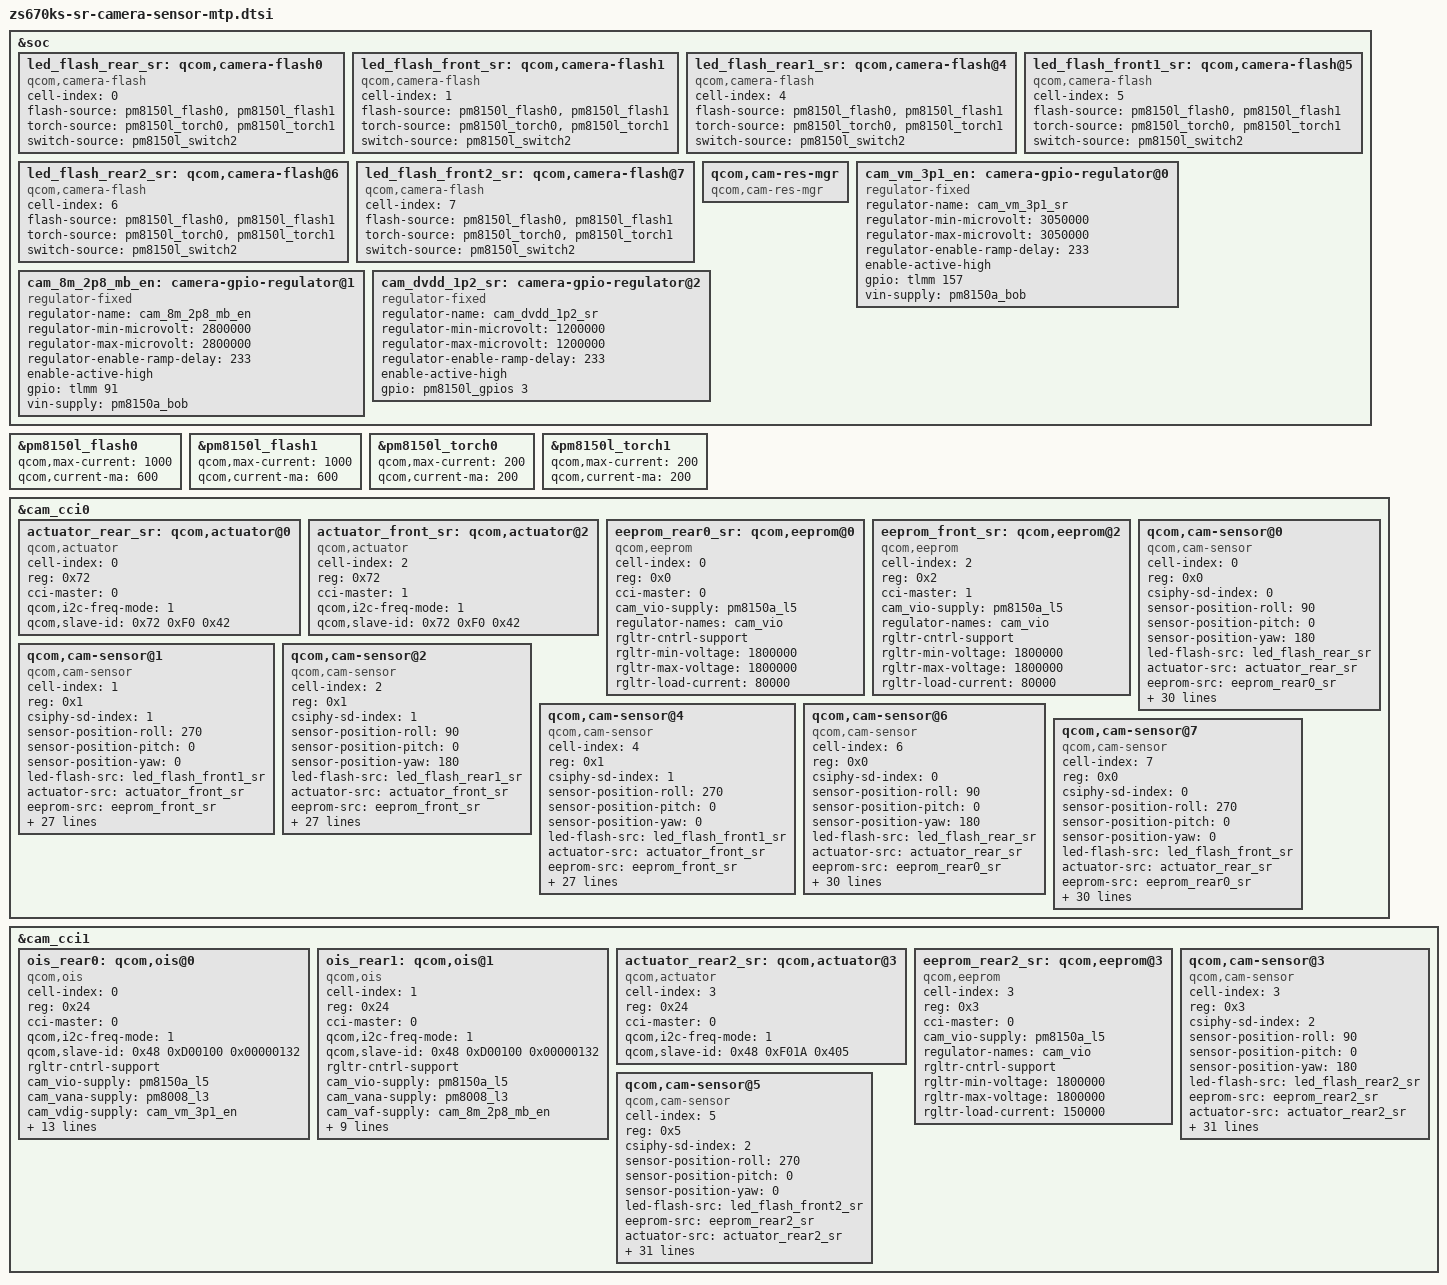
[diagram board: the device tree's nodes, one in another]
#include <dt-bindings/clock/qcom,camcc-kona.h>

&soc {
	led_flash_rear_sr: qcom,camera-flash0 {
		cell-index = <0>;
		compatible = "qcom,camera-flash";
		flash-source = <&pm8150l_flash0 &pm8150l_flash1>;
		torch-source = <&pm8150l_torch0 &pm8150l_torch1>;
		switch-source = <&pm8150l_switch2>;
		status = "ok";
	};//686_rear

	led_flash_front_sr: qcom,camera-flash1 {
		cell-index = <1>;
		compatible = "qcom,camera-flash";
		flash-source = <&pm8150l_flash0 &pm8150l_flash1>;
		torch-source = <&pm8150l_torch0 &pm8150l_torch1>;
		switch-source = <&pm8150l_switch2>;
		status = "ok";
	};//686_front

	led_flash_rear1_sr: qcom,camera-flash@4 {
		cell-index = <4>;
		compatible = "qcom,camera-flash";
		flash-source = <&pm8150l_flash0 &pm8150l_flash1>;
		torch-source = <&pm8150l_torch0 &pm8150l_torch1>;
		switch-source = <&pm8150l_switch2>;
		status = "ok";
	};//363_rear

	led_flash_front1_sr: qcom,camera-flash@5 {
		cell-index = <5>;
		compatible = "qcom,camera-flash";
		flash-source = <&pm8150l_flash0 &pm8150l_flash1>;
		torch-source = <&pm8150l_torch0 &pm8150l_torch1>;
		switch-source = <&pm8150l_switch2>;
		status = "ok";
	};//363_front

	led_flash_rear2_sr: qcom,camera-flash@6 {
		cell-index = <6>;
		compatible = "qcom,camera-flash";
		flash-source = <&pm8150l_flash0 &pm8150l_flash1>;
		torch-source = <&pm8150l_torch0 &pm8150l_torch1>;
		switch-source = <&pm8150l_switch2>;
		status = "ok";
	};//ov_rear


	led_flash_front2_sr: qcom,camera-flash@7 {
		cell-index = <7>;
		compatible = "qcom,camera-flash";
		flash-source = <&pm8150l_flash0 &pm8150l_flash1>;
		torch-source = <&pm8150l_torch0 &pm8150l_torch1>;
		switch-source = <&pm8150l_switch2>;
		status = "ok";
	};//ov_front


	qcom,cam-res-mgr {
		compatible = "qcom,cam-res-mgr";
		status = "ok";
	};
	//IMX686 VM 3.1V
	cam_vm_3p1_en: camera-gpio-regulator@0 {
		compatible = "regulator-fixed";
		regulator-name = "cam_vm_3p1_sr";
		regulator-min-microvolt = <3050000>;
		regulator-max-microvolt = <3050000>;
		regulator-enable-ramp-delay = <233>;
		enable-active-high;
		gpio = <&tlmm 157 0>;
		vin-supply = <&pm8150a_bob>;
	};
	cam_8m_2p8_mb_en: camera-gpio-regulator@1 {
		compatible = "regulator-fixed";
		regulator-name = "cam_8m_2p8_mb_en";
		regulator-min-microvolt = <2800000>;
		regulator-max-microvolt = <2800000>;
		regulator-enable-ramp-delay = <233>;
		enable-active-high;
		gpio = <&tlmm 91 0>;
		vin-supply = <&pm8150a_bob>;
	};

	//AVDD  CAM_DVDD_1P2 OV08A10
	cam_dvdd_1p2_sr: camera-gpio-regulator@2 {
		compatible = "regulator-fixed";
		regulator-name = "cam_dvdd_1p2_sr";
		regulator-min-microvolt = <1200000>;
		regulator-max-microvolt = <1200000>;
		regulator-enable-ramp-delay = <233>;
		enable-active-high;
		gpio = <&pm8150l_gpios 3 0>;
		//vin-supply = <&pm8150a-s4>;
	};
};
	&pm8150l_flash0 {
		qcom,max-current = <1000>;
		qcom,current-ma = <600>;
	};

	&pm8150l_flash1 {
		qcom,max-current = <1000>;
		qcom,current-ma = <600>;
	};
	&pm8150l_torch0 {
		qcom,max-current = <200>;
		qcom,current-ma = <200>;
	};

	&pm8150l_torch1 {
		qcom,max-current = <200>;
		qcom,current-ma = <200>;
	};
&cam_cci0 {
	
	actuator_rear_sr: qcom,actuator@0 { //for imx686 LC898249
		cell-index = <0>;
		reg = <0x72>;
		compatible = "qcom,actuator";
		cci-master = <0>;
		qcom,i2c-freq-mode = <1>;
		qcom,slave-id = <0x72 0xF0 0x42>;
		status = "ok";
  };


	//########### IMX363 ###########
	actuator_front_sr: qcom,actuator@2 {
		cell-index = <2>;
		reg = <0x72>;
		compatible = "qcom,actuator";
		cci-master = <1>;
		qcom,i2c-freq-mode = <1>;
		qcom,slave-id = <0x72 0xF0 0x42>;
		status = "ok";
	};

	eeprom_rear0_sr: qcom,eeprom@0 {
		cell-index = <0>;
		reg = <0x0>;
		cci-master = <0>;
		compatible = "qcom,eeprom";
		cam_vio-supply = <&pm8150a_l5>;    //MCAM0_DOVDD_T_1P8
		regulator-names = "cam_vio";
		rgltr-cntrl-support;
		rgltr-min-voltage = <1800000>;
		rgltr-max-voltage = <1800000>;
		rgltr-load-current = <80000>;
		status = "ok";
	}; 

	eeprom_front_sr: qcom,eeprom@2{
		cell-index = <2>;
		reg = <0x2>;
		cci-master = <1>;
		compatible = "qcom,eeprom";
	 	cam_vio-supply = <&pm8150a_l5>;    //PM8008_LDO6_1P8
		regulator-names = "cam_vio";
		rgltr-cntrl-support;
		rgltr-min-voltage = <1800000>;
		rgltr-max-voltage = <1800000>;
		rgltr-load-current = <80000>;
		status = "ok";
	};

	//########### imx686h_rear_16M ###########
	qcom,cam-sensor@0 {
		cell-index = <0>;
		compatible = "qcom,cam-sensor";
		reg = <0x0>;
		csiphy-sd-index = <0>;
		sensor-position-roll = <90>;
		sensor-position-pitch = <0>;
		sensor-position-yaw = <180>;
		led-flash-src = <&led_flash_rear_sr>;
		actuator-src = <&actuator_rear_sr>;
 		eeprom-src = <&eeprom_rear0_sr>;
		ois-src = <&ois_rear0>;
		cam_vio-supply = <&pm8008_l7>;          //CAM_AVDD1_2P9 
		cam_vana-supply = <&pm8008_l6>;      //CAM_AVDD_1P8 
		cam_v_custom1-supply = <&pm8150a_l5>;    //MCAM0_DOVDD_T_1P8 
		cam_v_custom2-supply = <&pm8008_l3>;    //MCAM0_DOVDD_T_2P9	
		cam_vdig-supply = <&pm8008_l1>;         //MCAM0_DVDD_T_1P1 
		cam_vaf-supply = <&cam_vm_3p1_en>;          //CAM0_VM_3P1_MB
		cam_clk-supply = <&titan_top_gdsc>;
		regulator-names = "cam_vio", "cam_vana", "cam_v_custom1","cam_v_custom2", "cam_vdig", "cam_vaf", "cam_clk";
		rgltr-cntrl-support;
		rgltr-min-voltage = <2950000 1850000 1800000 2900000 1104000 3050000 0>;
		rgltr-max-voltage = <2950000 1850000 1800000 2900000 1104000 3050000 0>;
		rgltr-load-current = <0 80000 80000 300000 0 0 0>;
		gpio-no-mux = <0>;
		pinctrl-names = "cam_default", "cam_suspend";
		pinctrl-0 = <&cam_sensor_mclk0_active>;
		pinctrl-1 = <&cam_sensor_mclk0_suspend>;
		gpios = <&tlmm 94 0>,
			<&tlmm 93 0>;
		gpio-reset = <1>;
		gpio-req-tbl-num = <0 1>;
		gpio-req-tbl-flags = <1 0>;
		gpio-req-tbl-label = "CAMIF_MCLK0",
					"CAM_RESET0";
		sensor-mode = <0>;
		cci-master = <0>;
		status = "ok";
		clocks = <&clock_camcc CAM_CC_MCLK0_CLK>;
		clock-names = "cam_clk";
		clock-cntl-level = "turbo";
		clock-rates = <19200000>;
	};


	//########### IMX363 front for 3rd Party ###########
	qcom,cam-sensor@1 {
		cell-index = <1>;
		compatible = "qcom,cam-sensor";
		reg = <0x1>;
		csiphy-sd-index = <1>;
		sensor-position-roll = <270>;
		sensor-position-pitch = <0>;
		sensor-position-yaw = <0>;
		led-flash-src = <&led_flash_front1_sr>;
		actuator-src = <&actuator_front_sr>;
		eeprom-src = <&eeprom_front_sr>;
		cam_vaf-supply = <&pm8150a_l7>;          //MVCM_2P8
		cam_vio-supply = <&pm8150a_l5>;			//CAM_DOVDD_F_1P8
		cam_vana-supply = <&pm8008_l4>;	//l4p cc wrong		//CAM_AVDD_F_2P8
		cam_vdig-supply = <&pm8008_l2>;		//MCAM0_DVDD_T1_1P1
		cam_clk-supply = <&titan_top_gdsc>;
		regulator-names = "cam_vaf", "cam_vio", "cam_vana", "cam_vdig", "cam_clk";
		rgltr-cntrl-support;
		rgltr-min-voltage = <2900000 1800000 2800000 1050000 0>;
		rgltr-max-voltage = <2900000 1800000 2800000 1050000 0>;
		rgltr-load-current = <140000 80000 80000 1050000 0 >;
		gpio-no-mux = <0>;
		pinctrl-names = "cam_default", "cam_suspend";
	 	pinctrl-0 = <&cam_sensor_mclk1_active>;
		pinctrl-1 = <&cam_sensor_mclk1_suspend>;
		gpios = <&tlmm 95 0>,
			<&tlmm 92 0>;
		gpio-reset = <1>;
		gpio-req-tbl-num = <0 1>;
		gpio-req-tbl-flags = <1 0>;
		gpio-req-tbl-label = "CAMIF_MCLK1",
					"CAM_RESET1";
		sensor-mode = <0>;
		cci-master = <1>;
		status = "ok";
		clocks = <&clock_camcc CAM_CC_MCLK1_CLK>;
		clock-names = "cam_clk";
		clock-cntl-level = "turbo";
		clock-rates = <19200000>;
	};



	//########### IMX363 back ###########
	qcom,cam-sensor@2 {
		cell-index = <2>;
		compatible = "qcom,cam-sensor";
		reg = <0x1>;
		csiphy-sd-index = <1>;
		sensor-position-roll = <90>;
		sensor-position-pitch = <0>;
		sensor-position-yaw = <180>;
		led-flash-src = <&led_flash_rear1_sr>;
		actuator-src = <&actuator_front_sr>;
		eeprom-src = <&eeprom_front_sr>;
		cam_vaf-supply = <&pm8150a_l7>;          //MVCM_2P8
		cam_vio-supply = <&pm8150a_l5>;			//CAM_DOVDD_F_1P8
		cam_vana-supply = <&pm8008_l4>;	//l4p cc wrong		//CAM_AVDD_F_2P8
		cam_vdig-supply = <&pm8008_l2>;		//MCAM0_DVDD_T1_1P1
		cam_clk-supply = <&titan_top_gdsc>;
		regulator-names = "cam_vaf", "cam_vio", "cam_vana", "cam_vdig", "cam_clk";
		rgltr-cntrl-support;
		rgltr-min-voltage = <2900000 1800000 2800000 1050000 0>;
		rgltr-max-voltage = <2900000 1800000 2800000 1050000 0>;
		rgltr-load-current = <140000 80000 80000 1050000 0 >;
		gpio-no-mux = <0>;
		pinctrl-names = "cam_default", "cam_suspend";
	 	pinctrl-0 = <&cam_sensor_mclk1_active>;
		pinctrl-1 = <&cam_sensor_mclk1_suspend>;
		gpios = <&tlmm 95 0>,
			<&tlmm 92 0>;
		gpio-reset = <1>;
		gpio-req-tbl-num = <0 1>;
		gpio-req-tbl-flags = <1 0>;
		gpio-req-tbl-label = "CAMIF_MCLK1",
					"CAM_RESET1";
		sensor-mode = <0>;
		cci-master = <1>;
		status = "ok";
		clocks = <&clock_camcc CAM_CC_MCLK1_CLK>;
		clock-names = "cam_clk";
		clock-cntl-level = "turbo";
		clock-rates = <19200000>;
	};


	//########### IMX363 front  for ASUS camera ###########
	qcom,cam-sensor@4 {
		cell-index = <4>;
		compatible = "qcom,cam-sensor";
		reg = <0x1>;
		csiphy-sd-index = <1>;
		sensor-position-roll = <270>;
		sensor-position-pitch = <0>;
		sensor-position-yaw = <0>;
		led-flash-src = <&led_flash_front1_sr>;
		actuator-src = <&actuator_front_sr>;
		eeprom-src = <&eeprom_front_sr>;
		cam_vaf-supply = <&pm8150a_l7>;          //MVCM_2P8
		cam_vio-supply = <&pm8150a_l5>;			//CAM_DOVDD_F_1P8
		cam_vana-supply = <&pm8008_l4>;	//l4p cc wrong		//CAM_AVDD_F_2P8
		cam_vdig-supply = <&pm8008_l2>;		//MCAM0_DVDD_T1_1P1
		cam_clk-supply = <&titan_top_gdsc>;
		regulator-names = "cam_vaf", "cam_vio", "cam_vana", "cam_vdig", "cam_clk";
		rgltr-cntrl-support;
		rgltr-min-voltage = <2900000 1800000 2800000 1050000 0>;
		rgltr-max-voltage = <2900000 1800000 2800000 1050000 0>;
		rgltr-load-current = <140000 80000 80000 1050000 0 >;
		gpio-no-mux = <0>;
		pinctrl-names = "cam_default", "cam_suspend";
	 	pinctrl-0 = <&cam_sensor_mclk1_active>;
		pinctrl-1 = <&cam_sensor_mclk1_suspend>;
		gpios = <&tlmm 95 0>,
			<&tlmm 92 0>;
		gpio-reset = <1>;
		gpio-req-tbl-num = <0 1>;
		gpio-req-tbl-flags = <1 0>;
		gpio-req-tbl-label = "CAMIF_MCLK1",
					"CAM_RESET1";
		sensor-mode = <0>;
		cci-master = <1>;
		status = "ok";
		clocks = <&clock_camcc CAM_CC_MCLK1_CLK>;
		clock-names = "cam_clk";
		clock-cntl-level = "turbo";
		clock-rates = <19200000>;
	};
	
		//########### imx686h_rear ###########
	qcom,cam-sensor@6 {
		cell-index = <6>;
		compatible = "qcom,cam-sensor";
		reg = <0x0>;
		csiphy-sd-index = <0>;
		sensor-position-roll = <90>;
		sensor-position-pitch = <0>;
		sensor-position-yaw = <180>;
		led-flash-src = <&led_flash_rear_sr>;
		actuator-src = <&actuator_rear_sr>;
		eeprom-src = <&eeprom_rear0_sr>;
		ois-src = <&ois_rear0>;
		cam_vio-supply = <&pm8008_l7>;          //CAM_AVDD1_2P9 
		cam_vana-supply = <&pm8008_l6>;      //CAM_AVDD_1P8 
		cam_v_custom1-supply = <&pm8150a_l5>;    //MCAM0_DOVDD_T_1P8 
		cam_v_custom2-supply = <&pm8008_l3>;    //MCAM0_DOVDD_T_2P9	
		cam_vdig-supply = <&pm8008_l1>;         //MCAM0_DVDD_T_1P1 
		cam_vaf-supply = <&cam_vm_3p1_en>;          //CAM0_VM_3P1_MB
		cam_clk-supply = <&titan_top_gdsc>;
		regulator-names = "cam_vio", "cam_vana", "cam_v_custom1","cam_v_custom2", "cam_vdig", "cam_vaf", "cam_clk";
		rgltr-cntrl-support;
		rgltr-min-voltage = <2950000 1850000 1800000 2900000 1104000 3050000 0>;
		rgltr-max-voltage = <2950000 1850000 1800000 2900000 1104000 3050000 0>;
		rgltr-load-current = <0 80000 80000 300000 0 0 0>;
		gpio-no-mux = <0>;
		pinctrl-names = "cam_default", "cam_suspend";
		pinctrl-0 = <&cam_sensor_mclk0_active>;
		pinctrl-1 = <&cam_sensor_mclk0_suspend>;
		gpios = <&tlmm 94 0>,
			<&tlmm 93 0>;
		gpio-reset = <1>;
		gpio-req-tbl-num = <0 1>;
		gpio-req-tbl-flags = <1 0>;
		gpio-req-tbl-label = "CAMIF_MCLK0",
					"CAM_RESET0";
		sensor-mode = <0>;
		cci-master = <0>;
		status = "ok";
		clocks = <&clock_camcc CAM_CC_MCLK0_CLK>;
		clock-names = "cam_clk";
		clock-cntl-level = "turbo";
		clock-rates = <19200000>;
	};
	
	
		//########### imx686h_front ###########
	qcom,cam-sensor@7 {
		cell-index = <7>;
		compatible = "qcom,cam-sensor";
		reg = <0x0>;
		csiphy-sd-index = <0>;
		sensor-position-roll = <270>;
		sensor-position-pitch = <0>;
		sensor-position-yaw = <0>;
		led-flash-src = <&led_flash_front_sr>;
		actuator-src = <&actuator_rear_sr>;
		eeprom-src = <&eeprom_rear0_sr>;
		ois-src = <&ois_rear0>;
		cam_vio-supply = <&pm8008_l7>;          //CAM_AVDD1_2P9 
		cam_vana-supply = <&pm8008_l6>;      //CAM_AVDD_1P8 
		cam_v_custom1-supply = <&pm8150a_l5>;    //MCAM0_DOVDD_T_1P8 
		cam_v_custom2-supply = <&pm8008_l3>;    //MCAM0_DOVDD_T_2P9	
		cam_vdig-supply = <&pm8008_l1>;         //MCAM0_DVDD_T_1P1 
		cam_vaf-supply = <&cam_vm_3p1_en>;          //CAM0_VM_3P1_MB
		cam_clk-supply = <&titan_top_gdsc>;
		regulator-names = "cam_vio", "cam_vana", "cam_v_custom1","cam_v_custom2", "cam_vdig", "cam_vaf", "cam_clk";
		rgltr-cntrl-support;
		rgltr-min-voltage = <2950000 1850000 1800000 2900000 1104000 3050000 0>;
		rgltr-max-voltage = <2950000 1850000 1800000 2900000 1104000 3050000 0>;
		rgltr-load-current = <0 80000 80000 300000 0 0 0>;
		gpio-no-mux = <0>;
		pinctrl-names = "cam_default", "cam_suspend";
		pinctrl-0 = <&cam_sensor_mclk0_active>;
		pinctrl-1 = <&cam_sensor_mclk0_suspend>;
		gpios = <&tlmm 94 0>,
			<&tlmm 93 0>;
		gpio-reset = <1>;
		gpio-req-tbl-num = <0 1>;
		gpio-req-tbl-flags = <1 0>;
		gpio-req-tbl-label = "CAMIF_MCLK0",
					"CAM_RESET0";
		sensor-mode = <0>;
		cci-master = <0>;
		status = "ok";
		clocks = <&clock_camcc CAM_CC_MCLK0_CLK>;
		clock-names = "cam_clk";
		clock-cntl-level = "turbo";
		clock-rates = <19200000>;
	};
	
};

&cam_cci1 {

	ois_rear0: qcom,ois@0 {
		cell-index = <0>;
		reg = <0x24>;
		compatible = "qcom,ois";
		cci-master = <0>;
		qcom,i2c-freq-mode = <1>;
		qcom,slave-id = <0x48 0xD00100 0x00000132>;

		rgltr-cntrl-support;
		cam_vio-supply = <&pm8150a_l5>;
		cam_vana-supply = <&pm8008_l3>;
		cam_vdig-supply = <&cam_vm_3p1_en>;
		cam_vaf-supply = <&cam_8m_2p8_mb_en>;

		regulator-names = "cam_vio","cam_vana","cam_vdig","cam_vaf";
		rgltr-min-voltage = <1800000 2900000 3050000 2800000>;
		rgltr-max-voltage = <1800000 2900000 3050000 2800000>;
		rgltr-load-current = <80000 300000 0 300000>;

		qcom,cam-power-seq-type = "cam_vio","cam_vana","cam_vdig","cam_vaf";
		qcom,cam-power-seq-cfg-val = <1800000 2900000 3050000 2800000>;
		qcom,cam-power-seq-delay = <0 0 1 1>;//delay 100ms for OIS

		status = "ok";
	};

	ois_rear1: qcom,ois@1 {
		cell-index = <1>;
		reg = <0x24>;
		compatible = "qcom,ois";
		cci-master = <0>;
		qcom,i2c-freq-mode = <1>;
		qcom,slave-id = <0x48 0xD00100 0x00000132>;

		rgltr-cntrl-support;
		cam_vio-supply = <&pm8150a_l5>;
		cam_vana-supply = <&pm8008_l3>;
		cam_vaf-supply = <&cam_8m_2p8_mb_en>;

		regulator-names = "cam_vio","cam_vana","cam_vaf";
		rgltr-min-voltage = <1800000 2900000 2800000>;
		rgltr-max-voltage = <1800000 2900000 2800000>;
		rgltr-load-current = <150000 300000 1200000>;

		qcom,cam-power-seq-type = "cam_vio","cam_vana","cam_vaf";
		qcom,cam-power-seq-cfg-val = <1800000 2900000 2800000>;
		qcom,cam-power-seq-delay = <0 0 1>;//delay 1ms for VIO, delay 100ms for OIS

		status = "ok";
	};

	actuator_rear2_sr: qcom,actuator@3{
		cell-index = <3>;
		reg = <0x24>;
		compatible = "qcom,actuator";
		cci-master = <0>;
	        qcom,i2c-freq-mode = <1>;
	        qcom,slave-id = <0x48 0xF01A 0x405>;
		status = "ok";
	};

	eeprom_rear2_sr: qcom,eeprom@3{
		cell-index = <3>;
		reg = <0x3>;
		cci-master = <0>;
		compatible = "qcom,eeprom";
		cam_vio-supply = <&pm8150a_l5>;    //CAM012_GYRO_EEPROM_DOVDD_1P8_MB
		regulator-names = "cam_vio";
		rgltr-cntrl-support;
		rgltr-min-voltage = <1800000>;
		rgltr-max-voltage = <1800000>;
		rgltr-load-current = <150000>;
		status = "ok";
	};
    //######## OV08A_REAR #########
	qcom,cam-sensor@3 {
		cell-index = <3>;
		compatible = "qcom,cam-sensor";
		reg = <0x3>;
		csiphy-sd-index = <2>;
		sensor-position-roll = <90>;
		sensor-position-pitch = <0>;
		sensor-position-yaw = <180>;
		led-flash-src = <&led_flash_rear2_sr>;
		eeprom-src = <&eeprom_rear2_sr>;
		actuator-src = <&actuator_rear2_sr>;
		ois-src = <&ois_rear1>;
		cam_vio-supply = <&pm8150a_l5>;
		//cam_bob-supply = <&pm8150a_bob>;
		cam_vana-supply = <&L5P>;
		cam_vdig-supply = <&cam_dvdd_1p2_sr>;			//CAM_8M_DVDD_1P2_EN
		cam_v_custom1-supply = <&pm8008_l3>;    //MCAM0_DOVDD_T_2P9
		cam_v_custom2-supply = <&cam_8m_2p8_mb_en>;    //CAM2_VM_2P8_MB
		cam_clk-supply = <&titan_top_gdsc>;
                regulator-names = "cam_vio", "cam_vana", "cam_vdig", "cam_v_custom1", "cam_v_custom2", "cam_clk";
		rgltr-cntrl-support;
		rgltr-min-voltage = <1800000 2800000 1200000 2900000 2800000 0>;
		rgltr-max-voltage = <1800000 2800000 1200000 2900000 2800000 0>;
		rgltr-load-current = <150000 80000 1200000 300000 1200000 0 >;
		gpio-no-mux = <0>;
		pinctrl-names = "cam_default", "cam_suspend";
		pinctrl-0 = <&cam_sensor_mclk2_active
				 &cam_sensor_active_3>;
		pinctrl-1 = <&cam_sensor_mclk2_suspend
				 &cam_sensor_suspend_3>;
		gpios = <&tlmm 96 0>,
			<&tlmm 109 0>;
		gpio-reset = <1>;
		gpio-req-tbl-num = <0 1>;
		gpio-req-tbl-flags = <1 0>;
		gpio-req-tbl-label = "CAMIF_MCLK2",
					"CAM_RESET2";
		sensor-mode = <0>;
		cci-master = <0>;
		status = "ok";
		clocks = <&clock_camcc CAM_CC_MCLK2_CLK>;
		clock-names = "cam_clk";
		clock-cntl-level = "turbo";
		clock-rates = <19200000>;
	};

    //######## OV08A_FRONT #########
	qcom,cam-sensor@5 {
		cell-index = <5>;
		compatible = "qcom,cam-sensor";
		reg = <0x5>;
		csiphy-sd-index = <2>;
		sensor-position-roll = <270>;
		sensor-position-pitch = <0>;
		sensor-position-yaw = <0>;
		led-flash-src = <&led_flash_front2_sr>;
		eeprom-src = <&eeprom_rear2_sr>;
		actuator-src = <&actuator_rear2_sr>;
		ois-src = <&ois_rear1>;
		cam_vio-supply = <&pm8150a_l5>;
		//cam_bob-supply = <&pm8150a_bob>;
		cam_vana-supply = <&L5P>;
		cam_vdig-supply = <&cam_dvdd_1p2_sr>;			//CAM_8M_DVDD_1P2_EN
		cam_v_custom1-supply = <&pm8008_l3>;    //MCAM0_DOVDD_T_2P9
		cam_v_custom2-supply = <&cam_8m_2p8_mb_en>;    //CAM2_VM_2P8_MB
		cam_clk-supply = <&titan_top_gdsc>;
                regulator-names = "cam_vio", "cam_vana", "cam_vdig", "cam_v_custom1", "cam_v_custom2", "cam_clk";
		rgltr-cntrl-support;
		rgltr-min-voltage = <1800000 2800000 1200000 2900000 2800000 0>;
		rgltr-max-voltage = <1800000 2800000 1200000 2900000 2800000 0>;
		rgltr-load-current = <150000 80000 1200000 300000 1200000 0 >;
		gpio-no-mux = <0>;
		pinctrl-names = "cam_default", "cam_suspend";
		pinctrl-0 = <&cam_sensor_mclk2_active
				 &cam_sensor_active_3>;
		pinctrl-1 = <&cam_sensor_mclk2_suspend
				 &cam_sensor_suspend_3>;
		gpios = <&tlmm 96 0>,
			<&tlmm 109 0>;
		gpio-reset = <1>;
		gpio-req-tbl-num = <0 1>;
		gpio-req-tbl-flags = <1 0>;
		gpio-req-tbl-label = "CAMIF_MCLK2",
					"CAM_RESET2";
		sensor-mode = <0>;
		cci-master = <0>;
		status = "ok";
		clocks = <&clock_camcc CAM_CC_MCLK2_CLK>;
		clock-names = "cam_clk";
		clock-cntl-level = "turbo";
		clock-rates = <19200000>;
	};

};

